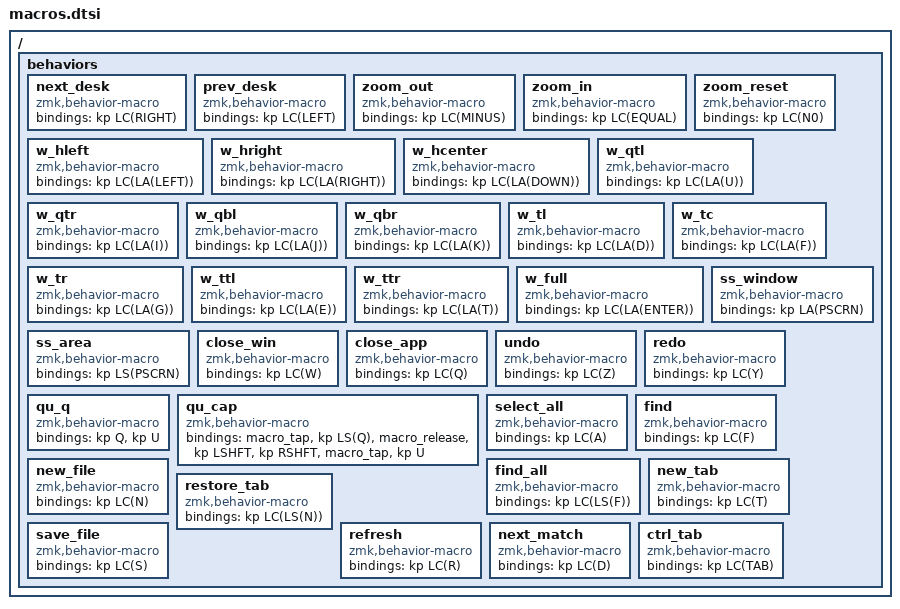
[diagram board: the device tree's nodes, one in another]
#include <dt-bindings/zmk/behaviors.h>
#include <dt-bindings/zmk/keys.h>
#include <zmk-helpers/helper.h>

// Switch Language
// ZMK_MACRO(kn_en, bindings = <&kp LA(LC(SPACE))>;)

// Navigation
ZMK_MACRO(next_desk, bindings = <&kp LC(RIGHT) >;)
ZMK_MACRO(prev_desk, bindings = <&kp LC(LEFT)>;)

// Zoom
ZMK_MACRO(zoom_out, bindings = <&kp LC(MINUS)>;)
ZMK_MACRO(zoom_in,  bindings = <&kp LC(EQUAL)>;)
ZMK_MACRO(zoom_reset,  bindings = <&kp LC(N0)>;)

// Windows Management - Half
ZMK_MACRO(w_hleft, bindings = <&kp LC(LA(LEFT))>;)
ZMK_MACRO(w_hright, bindings = <&kp LC(LA(RIGHT))>;)
ZMK_MACRO(w_hcenter, bindings = <&kp LC(LA(DOWN))>;)

// Windows Management - Quarter
ZMK_MACRO(w_qtl, bindings = <&kp LC(LA(U))>;)
ZMK_MACRO(w_qtr, bindings = <&kp LC(LA(I))>;)
ZMK_MACRO(w_qbl, bindings = <&kp LC(LA(J))>;)
ZMK_MACRO(w_qbr, bindings = <&kp LC(LA(K))>;)

// Windows Management - Third
ZMK_MACRO(w_tl, bindings = <&kp LC(LA(D))>;)
ZMK_MACRO(w_tc, bindings = <&kp LC(LA(F))>;)
ZMK_MACRO(w_tr, bindings = <&kp LC(LA(G))>;)

// Windows Management - 2 Third
ZMK_MACRO(w_ttl, bindings = <&kp LC(LA(E))>;)
ZMK_MACRO(w_ttr, bindings = <&kp LC(LA(T))>;)

// Windows Management - Fullscreen
ZMK_MACRO(w_full, bindings = <&kp LC(LA(ENTER))>;)

// Screenshots
ZMK_MACRO(ss_window, bindings = <&kp LA(PSCRN)>;) 
ZMK_MACRO(ss_area, bindings = <&kp LS(PSCRN)>;)

// Close windows
ZMK_MACRO(close_win, bindings = <&kp LC(W)>;) 
ZMK_MACRO(close_app, bindings = <&kp LC(Q)>;)

// Undo Redo
ZMK_MACRO(undo, bindings = <&kp LC(Z)>;) 
ZMK_MACRO(redo, bindings = <&kp LC(Y)>;)

// qu - q
ZMK_MACRO(qu_q, bindings = <&kp Q &kp U>;)
ZMK_MACRO(qu_cap,
    bindings =
        <&macro_tap &kp LS(Q)>,
        <&macro_release &kp LSHFT &kp RSHFT>,
        <&macro_tap &kp U>;
)
// Common actions
ZMK_MACRO(select_all,             bindings = <&kp LC(A)>;) 
ZMK_MACRO(find,                   bindings = <&kp LC(F)>;) 
ZMK_MACRO(find_all,               bindings = <&kp LC(LS(F))>;) 
ZMK_MACRO(new_file,               bindings = <&kp LC(N)>;)
ZMK_MACRO(new_tab,                bindings = <&kp LC(T)>;)
ZMK_MACRO(restore_tab,            bindings = <&kp LC(LS(N))>;) 
ZMK_MACRO(save_file,              bindings = <&kp LC(S)>;)
ZMK_MACRO(refresh,                bindings = <&kp LC(R)>;)
ZMK_MACRO(next_match,             bindings = <&kp LC(D)>;)
ZMK_MACRO(ctrl_tab,               bindings = <&kp LC(TAB)>;)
